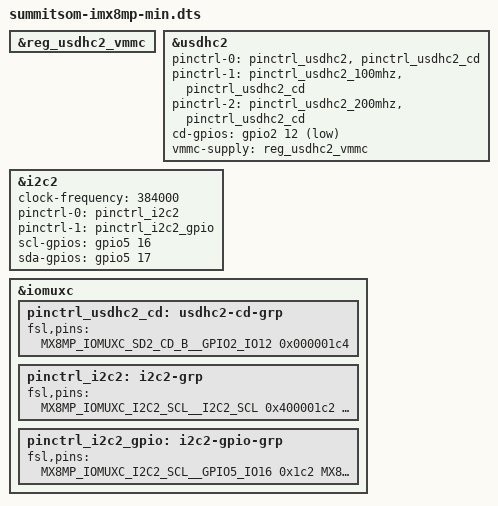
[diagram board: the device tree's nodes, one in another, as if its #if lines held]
// SPDX-License-Identifier: LicenseRef-Ezurio-Clause
/*
 * Copyright 2021 Ezurio
 */

/dts-v1/;

#include "summitsom-imx8mp.dtsi"

&reg_usdhc2_vmmc {
	status = "okay";
};

&usdhc2 {
	pinctrl-names = "default", "state_100mhz", "state_200mhz";
	pinctrl-0 = <&pinctrl_usdhc2>, <&pinctrl_usdhc2_cd>;
	pinctrl-1 = <&pinctrl_usdhc2_100mhz>, <&pinctrl_usdhc2_cd>;
	pinctrl-2 = <&pinctrl_usdhc2_200mhz>, <&pinctrl_usdhc2_cd>;

	cd-gpios = <&gpio2 12 GPIO_ACTIVE_LOW>;

	vmmc-supply = <&reg_usdhc2_vmmc>;

	status = "okay";
};

#ifdef CONFIG_SUMMIT_SOM_DVK
&i2c2 {
	clock-frequency = <384000>;
	pinctrl-names = "default", "gpio";
	pinctrl-0 = <&pinctrl_i2c2>;
	pinctrl-1 = <&pinctrl_i2c2_gpio>;
	scl-gpios = <&gpio5 16 (GPIO_ACTIVE_HIGH | GPIO_OPEN_DRAIN)>;
	sda-gpios = <&gpio5 17 (GPIO_ACTIVE_HIGH | GPIO_OPEN_DRAIN)>;
	status = "okay";
};
#endif

&iomuxc {
	pinctrl_usdhc2_cd: usdhc2-cd-grp {
		fsl,pins = <
			MX8MP_IOMUXC_SD2_CD_B__GPIO2_IO12		0x000001c4
		>;
	};

	pinctrl_i2c2: i2c2-grp {
		fsl,pins = <
			MX8MP_IOMUXC_I2C2_SCL__I2C2_SCL			0x400001c2
			MX8MP_IOMUXC_I2C2_SDA__I2C2_SDA			0x400001c2
		>;
	};

	pinctrl_i2c2_gpio: i2c2-gpio-grp {
		fsl,pins = <
			MX8MP_IOMUXC_I2C2_SCL__GPIO5_IO16        	0x1c2
			MX8MP_IOMUXC_I2C2_SDA__GPIO5_IO17        	0x1c2
		>;
	};
};
